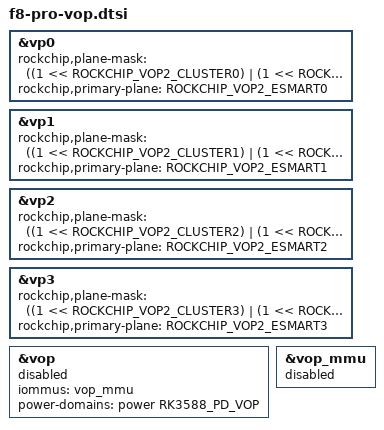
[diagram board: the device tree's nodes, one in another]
// SPDX-License-Identifier: GPL-2.0-only
// Checked against pinned RK3588 VOP2 physical IDs; compile-check only.
#include <dt-bindings/display/rockchip_vop.h>

&vp0 {
	rockchip,plane-mask = <((1 << ROCKCHIP_VOP2_CLUSTER0) | (1 << ROCKCHIP_VOP2_ESMART0))>;
	rockchip,primary-plane = <ROCKCHIP_VOP2_ESMART0>;
};

&vp1 {
	rockchip,plane-mask = <((1 << ROCKCHIP_VOP2_CLUSTER1) | (1 << ROCKCHIP_VOP2_ESMART1))>;
	rockchip,primary-plane = <ROCKCHIP_VOP2_ESMART1>;
};

&vp2 {
	rockchip,plane-mask = <((1 << ROCKCHIP_VOP2_CLUSTER2) | (1 << ROCKCHIP_VOP2_ESMART2))>;
	rockchip,primary-plane = <ROCKCHIP_VOP2_ESMART2>;
};

&vp3 {
	rockchip,plane-mask = <((1 << ROCKCHIP_VOP2_CLUSTER3) | (1 << ROCKCHIP_VOP2_ESMART3))>;
	rockchip,primary-plane = <ROCKCHIP_VOP2_ESMART3>;
};

&vop {
	iommus = <&vop_mmu>;
	power-domains = <&power RK3588_PD_VOP>;
	status = "disabled";
};
&vop_mmu { status = "disabled"; };
